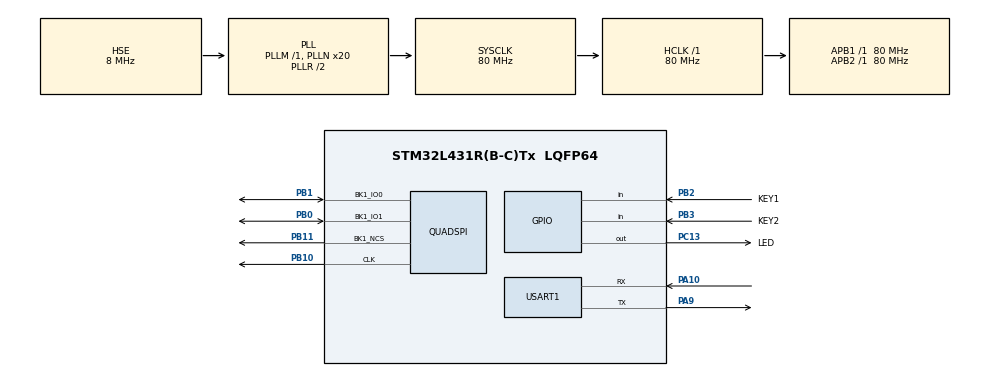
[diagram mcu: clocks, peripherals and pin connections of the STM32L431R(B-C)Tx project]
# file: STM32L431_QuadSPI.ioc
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Mcu.Family=STM32L4
Mcu.Name=STM32L431R(B-C)Tx
Mcu.Package=LQFP64
NVIC.PriorityGroup=NVIC_PRIORITYGROUP_4
PA10.GPIO_PuPd=GPIO_NOPULL
PA10.Mode=Asynchronous
PA10.Signal=USART1_RX
PA9.GPIO_PuPd=GPIO_PULLUP
PA9.Mode=Asynchronous
PA9.Signal=USART1_TX
PB0.Mode=Single Bank 1 2IOs
PB0.Signal=QUADSPI_BK1_IO1
PB1.Mode=Single Bank 1 2IOs
PB1.Signal=QUADSPI_BK1_IO0
PB10.Mode=Single Bank 1 2IOs
PB10.Signal=QUADSPI_CLK
PB11.Mode=Single Bank 1 2IOs
PB11.Signal=QUADSPI_BK1_NCS
PB2.GPIO_Label=KEY1
PB2.GPIO_PuPd=GPIO_PULLUP
PB2.Signal=GPIO_Input
PB3\ (JTDO-TRACESWO).GPIO_Label=KEY2
PB3\ (JTDO-TRACESWO).GPIO_PuPd=GPIO_PULLUP
PB3\ (JTDO-TRACESWO).Signal=GPIO_Input
PC13.GPIO_Label=LED
PC13.Signal=GPIO_Output
PH0-OSC_IN\ (PH0).Mode=HSE-External-Oscillator
PH0-OSC_IN\ (PH0).Signal=RCC_OSC_IN
PH1-OSC_OUT\ (PH1).Mode=HSE-External-Oscillator
PH1-OSC_OUT\ (PH1).Signal=RCC_OSC_OUT
ProjectManager.HeapSize=0x200
ProjectManager.StackSize=0x400
ProjectManager.TargetToolchain=SW4STM32
QUADSPI.ChipSelectHighTime=QSPI_CS_HIGH_TIME_4_CYCLE
QUADSPI.ClockPrescaler=0
QUADSPI.FifoThreshold=4
QUADSPI.FlashSize=24
QUADSPI.SampleShifting=QSPI_SAMPLE_SHIFTING_HALFCYCLE
RCC.ADCFreq_Value=32000000
RCC.AHBFreq_Value=80000000
RCC.APB1Freq_Value=80000000
RCC.APB1TimFreq_Value=80000000
RCC.APB2Freq_Value=80000000
RCC.APB2TimFreq_Value=80000000
RCC.CortexFreq_Value=80000000
RCC.HCLKFreq_Value=80000000
RCC.HSE_VALUE=8000000
RCC.HSI48_VALUE=48000000
RCC.HSI_VALUE=16000000
RCC.LSE_VALUE=32768
RCC.MSI_VALUE=4000000
RCC.PLLN=20
RCC.PLLSourceVirtual=RCC_PLLSOURCE_HSE
RCC.SYSCLKFreq_VALUE=80000000
RCC.SYSCLKSource=RCC_SYSCLKSOURCE_PLLCLK
RCC.VCOOutputFreq_Value=160000000
USART1.VirtualMode-Asynchronous=VM_ASYNC
board=custom

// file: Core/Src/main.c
/* USER CODE BEGIN Header */
/**
  ******************************************************************************
  * @file           : main.c
  * @brief          : Main program body
  ******************************************************************************
  * @attention
  *
  * <h2><center>&copy; Copyright (c) 2021 STMicroelectronics.
  * All rights reserved.</center></h2>
  *
  * This software component is licensed by ST under BSD 3-Clause license,
  * the "License"; You may not use this file except in compliance with the
  * License. You may obtain a copy of the License at:
  *                        opensource.org/licenses/BSD-3-Clause
  *
  ******************************************************************************
  */
/* USER CODE END Header */
#include "main.h"
#include "quadspi.h"
#include "usart.h"
#include "gpio.h"

/* USER CODE BEGIN Includes */
#include "user_qspi_flash.h"
/* USER CODE END Includes */

void SystemClock_Config(void);

int main(void)
{
  /* USER CODE BEGIN 1 */
  uint32_t location1=0;
  uint32_t location2=4096;
  uint32_t W25xID;
  uint16_t ReadData[]={0};
  uint16_t ReadData_1[]={0};
  uint8_t writeData[]={"welcome to IoT"};
  uint8_t writeData_1[]={"第一个QuadSPI实验"};

  /* USER CODE END 1 */

  /* MCU Configuration--------------------------------------------------------*/

  /* Reset of all peripherals, Initializes the Flash interface and the Systick. */
  HAL_Init();

  /* Configure the system clock */
  SystemClock_Config();

  /* Initialize all configured peripherals */
  MX_GPIO_Init();
  MX_QUADSPI_Init();
  MX_USART1_UART_Init();
  /* USER CODE BEGIN 2 */
  hal_spi_flash_read(ReadData,sizeof(writeData),0);//读0位的数据
  /* USER CODE END 2 */

  /* Infinite loop */
  while (1)
  {

  }
}

void SystemClock_Config(void)
{
  RCC_OscInitTypeDef RCC_OscInitStruct = {0};
  RCC_ClkInitTypeDef RCC_ClkInitStruct = {0};
  RCC_PeriphCLKInitTypeDef PeriphClkInit = {0};

  /** Initializes the RCC Oscillators according to the specified parameters
  * in the RCC_OscInitTypeDef structure.
  */
  RCC_OscInitStruct.OscillatorType = RCC_OSCILLATORTYPE_HSE;
  RCC_OscInitStruct.HSEState = RCC_HSE_ON;
  RCC_OscInitStruct.PLL.PLLState = RCC_PLL_ON;
  RCC_OscInitStruct.PLL.PLLSource = RCC_PLLSOURCE_HSE;
  RCC_OscInitStruct.PLL.PLLM = 1;
  RCC_OscInitStruct.PLL.PLLN = 20;
  RCC_OscInitStruct.PLL.PLLP = RCC_PLLP_DIV7;
  RCC_OscInitStruct.PLL.PLLQ = RCC_PLLQ_DIV2;
  RCC_OscInitStruct.PLL.PLLR = RCC_PLLR_DIV2;
  if (HAL_RCC_OscConfig(&RCC_OscInitStruct) != HAL_OK)
  {
    Error_Handler();
  }
  /** Initializes the CPU, AHB and APB buses clocks
  */
  RCC_ClkInitStruct.ClockType = RCC_CLOCKTYPE_HCLK|RCC_CLOCKTYPE_SYSCLK
                              |RCC_CLOCKTYPE_PCLK1|RCC_CLOCKTYPE_PCLK2;
  RCC_ClkInitStruct.SYSCLKSource = RCC_SYSCLKSOURCE_PLLCLK;
  RCC_ClkInitStruct.AHBCLKDivider = RCC_SYSCLK_DIV1;
  RCC_ClkInitStruct.APB1CLKDivider = RCC_HCLK_DIV1;
  RCC_ClkInitStruct.APB2CLKDivider = RCC_HCLK_DIV1;

  if (HAL_RCC_ClockConfig(&RCC_ClkInitStruct, FLASH_LATENCY_4) != HAL_OK)
  {
    Error_Handler();
  }
  PeriphClkInit.PeriphClockSelection = RCC_PERIPHCLK_USART1;
  PeriphClkInit.Usart1ClockSelection = RCC_USART1CLKSOURCE_PCLK2;
  if (HAL_RCCEx_PeriphCLKConfig(&PeriphClkInit) != HAL_OK)
  {
    Error_Handler();
  }
  /** Configure the main internal regulator output voltage
  */
  if (HAL_PWREx_ControlVoltageScaling(PWR_REGULATOR_VOLTAGE_SCALE1) != HAL_OK)
  {
    Error_Handler();
  }
}

void Error_Handler(void)
{
}

/************************ (C) COPYRIGHT STMicroelectronics *****END OF FILE****/
